# RZT2ME register map
Vendor: Renesas Electronics Corporation; Series: RZT; File version: 1.00.00
CPU: other r0p0, little endian, MPU, no FPU, VTOR, 4 interrupt priority bits, 624 interrupts
Registers are 32-bit, read-write, reset 0x0 unless marked. A register's access mark holds for its fields unless they carry their own. Offsets are from the block's base; [hi:lo] are bit positions.

## MTU3 — Multi-Function Timer Pulse Unit Channel 3
Base 0x90001100
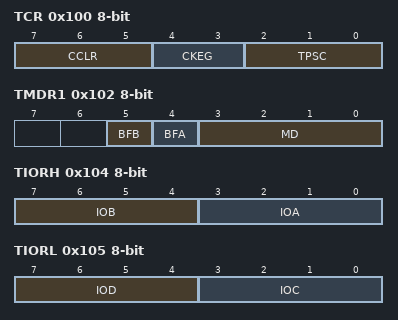
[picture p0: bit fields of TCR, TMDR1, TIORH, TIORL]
0x100 TCR 8-bit — Timer Control Register
  [7:5] CCLR — Counter Clear Source Select
  [4:3] CKEG — Clock Edge Select
    0=Count at rising edge; 1=Count at falling edge; 0b1x=Count at both edges
  [2:0] TPSC — Time Prescaler Select
0x102 TMDR1 8-bit — Timer Mode Register 1
  [5] BFB — Buffer Operation B
    0=TGRB and TGRD operate normally; 1=TGRB and TGRD used together for buffer operation
  [4] BFA — Buffer Operation A
    0=TGRA and TGRC operate normally; 1=TGRA and TGRC used together for buffer operation
  [3:0] MD — Mode Select
0x104 TIORH 8-bit — Timer I/O Control Register H
  [7:4] IOB — I/O Control B
  [3:0] IOA — I/O Control A
0x105 TIORL 8-bit — Timer I/O Control Register L
  [7:4] IOD — I/O Control B
  [3:0] IOC — I/O Control A
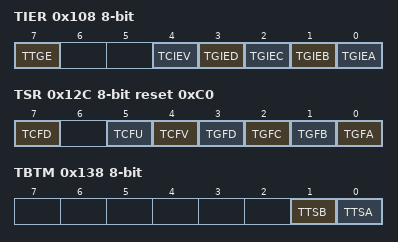
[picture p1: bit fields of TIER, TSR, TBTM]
0x108 TIER 8-bit — Timer Interrupt Enable Register
  [7] TTGE — A/D Converter Start Request Enable
    0=A/D converter start request generation disabled; 1=A/D converter start request generation enabled
  [4] TCIEV — Overflow Interrupt Enable
    0=Interrupt requests (TCIV) disabled; 1=Interrupt requests (TCIV) enabled
  [3] TGIED — TGR Interrupt Enable D
    0=Interrupt requests (TGID) disabled; 1=Interrupt requests (TGID) enabled
  [2] TGIEC — TGR Interrupt Enable C
    0=Interrupt requests (TGIC) disabled; 1=Interrupt requests (TGIC) enabled
  [1] TGIEB — TGR Interrupt Enable B
    0=Interrupt requests (TGIB) disabled; 1=Interrupt requests (TGIB) enabled
  [0] TGIEA — TGR Interrupt Enable A
    0=Interrupt requests (TGIA) disabled; 1=Interrupt requests (TGIA) enabled
0x110 TCNT 16-bit — Timer Counter
0x118 TGRA 16-bit reset 0xFFFF — Timer General Register A
0x11A TGRB 16-bit reset 0xFFFF — Timer General Register B
0x124 TGRC 16-bit reset 0xFFFF — Timer General Register C
0x126 TGRD 16-bit reset 0xFFFF — Timer General Register D
0x12C TSR 8-bit reset 0xC0 — Timer Status Register
  [7] TCFD ro — Count Direction Flag
    0=TCNT counts down; 1=TCNT counts up
  [5] TCFU — Underflow flag
    0=TCNT underflow has not occurred when MTU1 and MTU2 are in phase counting mode; 1=TCNT underflow has occurred when MTU1 and MTU2 are in phase counting mode
  [4] TCFV — Overflow flag
    0=TCNT overflow has not occurred; 1=TCNT overflow has occurred
  [3] TGFD — Input Capture/Output Compare Flag D
    0=TGRD input capture or compare match has not occurred; 1=TGRD input capture or compare match has occurred
  [2] TGFC — Input Capture/Output Compare Flag C
    0=TGRC input capture or compare match has not occurred; 1=TGRC input capture or compare match has occurred
  [1] TGFB — Input Capture/Output Compare Flag B
    0=TGRB input capture or compare match has not occurred; 1=TGRB input capture or compare match has occurred
  [0] TGFA — Input Capture/Output Compare Flag A
    0=TGRA input capture or compare match has not occurred; 1=TGRA input capture or compare match has occurred
0x138 TBTM 8-bit — Timer Buffer Operation Transfer Mode Register
  [1] TTSB — Timing Select B
    0=When compare match B occurs in each channel, data is transferred from TGRD to TGRB; 1=When TCNT is cleared in each channel, data is transferred from TGRD to TGRB
  [0] TTSA — Timing Select A
    0=When compare match A occurs in each channel, data is transferred from TGRC to TGRA; 1=When TCNT is cleared in each channel, data is transferred from TGRC to TGRA
0x14C TCR2 8-bit — Timer Control Register 2
  [2:0] TPSC2 — Time Prescaler Select
0x172 TGRE 16-bit reset 0xFFFF — Timer General Register E

## MTU6 — Multi-Function Timer Pulse Unit Channel 6
Base 0x90001900
Registers as MTU3; these are added or differ:
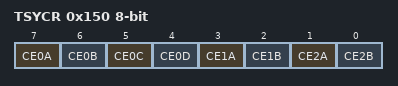
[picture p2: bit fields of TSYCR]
0x150 TSYCR 8-bit — Timer Synchronous Clear Register
  [7] CE0A — Clear Enable 0A
    0=Disables counter clearing by the MTU0.TGIA0 interrupt generation timing; 1=Enables counter clearing by the MTU0.TGIA0 interrupt generation timing
  [6] CE0B — Clear Enable 0B
    0=Disables counter clearing by the MTU0.TGIB0 interrupt generation timing; 1=Enables counter clearing by the MTU0.TGIB0 interrupt generation timing
  [5] CE0C — Clear Enable 0C
    0=Disables counter clearing by the MTU0.TGIC0 interrupt generation timing; 1=Enables counter clearing by the MTU0.TGIC0 interrupt generation timing
  [4] CE0D — Clear Enable 0D
    0=Disables counter clearing by the MTU0.TGID0 interrupt generation timing; 1=Enables counter clearing by the MTU0.TGID0 interrupt generation timing
  [3] CE1A — Clear Enable 1A
    0=Disables counter clearing by the MTU1.TGIA1 interrupt generation timing; 1=Enables counter clearing by the MTU1.TGIA1 interrupt generation timing
  [2] CE1B — Clear Enable 1B
    0=Disables counter clearing by the MTU1.TGIB1 interrupt generation timing; 1=Enables counter clearing by the MTU1.TGIB1 interrupt generation timing
  [1] CE2A — Clear Enable 2A
    0=Disables counter clearing by the MTU2.TGIA2 interrupt generation timing; 1=Enables counter clearing by the MTU2.TGIA2 interrupt generation timing
  [0] CE2B — Clear Enable 2B
    0=Disables counter clearing by the MTU2.TGIB2 interrupt generation timing; 1=Enables counter clearing by the MTU2.TGIB2 interrupt generation timing
